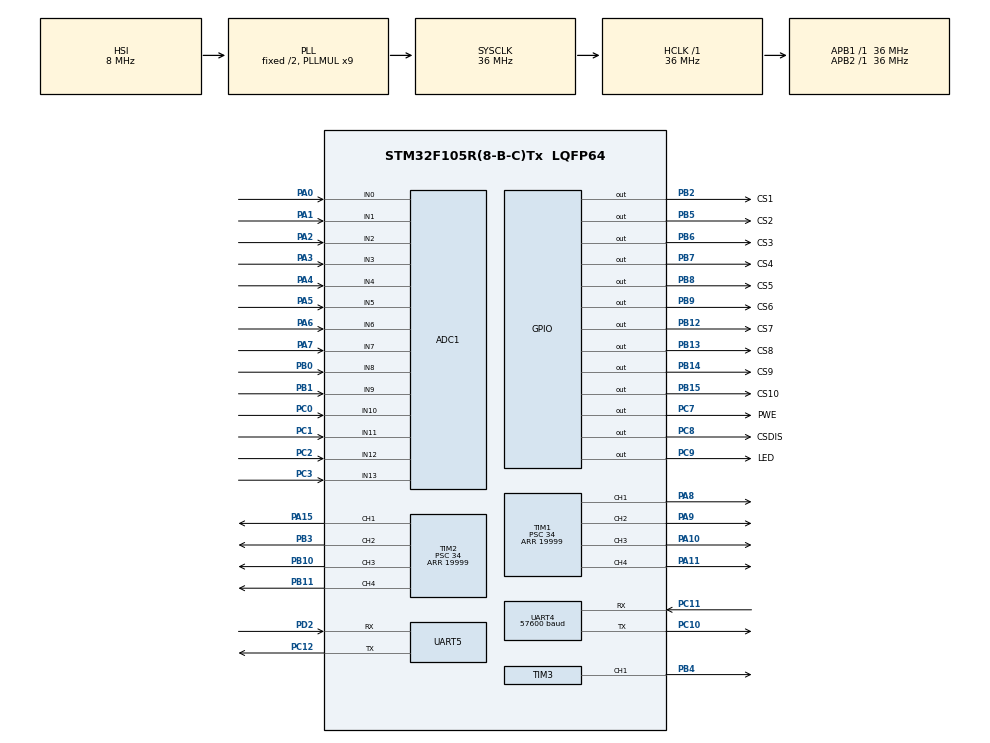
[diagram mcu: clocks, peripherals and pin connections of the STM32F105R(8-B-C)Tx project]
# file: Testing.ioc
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ADC1.Channel-0\#ChannelRegularConversion=ADC_CHANNEL_0
ADC1.Channel-1\#ChannelRegularConversion=ADC_CHANNEL_1
ADC1.Channel-10\#ChannelRegularConversion=ADC_CHANNEL_10
ADC1.Channel-11\#ChannelRegularConversion=ADC_CHANNEL_11
ADC1.Channel-12\#ChannelRegularConversion=ADC_CHANNEL_12
ADC1.Channel-13\#ChannelRegularConversion=ADC_CHANNEL_13
ADC1.Channel-14\#ChannelRegularConversion=ADC_CHANNEL_TEMPSENSOR
ADC1.Channel-2\#ChannelRegularConversion=ADC_CHANNEL_2
ADC1.Channel-3\#ChannelRegularConversion=ADC_CHANNEL_3
ADC1.Channel-4\#ChannelRegularConversion=ADC_CHANNEL_4
ADC1.Channel-5\#ChannelRegularConversion=ADC_CHANNEL_5
ADC1.Channel-6\#ChannelRegularConversion=ADC_CHANNEL_6
ADC1.Channel-7\#ChannelRegularConversion=ADC_CHANNEL_7
ADC1.Channel-8\#ChannelRegularConversion=ADC_CHANNEL_8
ADC1.Channel-9\#ChannelRegularConversion=ADC_CHANNEL_9
ADC1.ContinuousConvMode=ENABLE
ADC1.NbrOfConversion=15
ADC1.NbrOfConversionFlag=1
ADC1.Rank-0\#ChannelRegularConversion=1
ADC1.Rank-1\#ChannelRegularConversion=2
ADC1.Rank-10\#ChannelRegularConversion=11
ADC1.Rank-11\#ChannelRegularConversion=12
ADC1.Rank-12\#ChannelRegularConversion=13
ADC1.Rank-13\#ChannelRegularConversion=14
ADC1.Rank-14\#ChannelRegularConversion=15
ADC1.Rank-2\#ChannelRegularConversion=3
ADC1.Rank-3\#ChannelRegularConversion=4
ADC1.Rank-4\#ChannelRegularConversion=5
ADC1.Rank-5\#ChannelRegularConversion=6
ADC1.Rank-6\#ChannelRegularConversion=7
ADC1.Rank-7\#ChannelRegularConversion=8
ADC1.Rank-8\#ChannelRegularConversion=9
ADC1.Rank-9\#ChannelRegularConversion=10
ADC1.SamplingTime-0\#ChannelRegularConversion=ADC_SAMPLETIME_28CYCLES_5
ADC1.SamplingTime-1\#ChannelRegularConversion=ADC_SAMPLETIME_28CYCLES_5
ADC1.SamplingTime-10\#ChannelRegularConversion=ADC_SAMPLETIME_28CYCLES_5
ADC1.SamplingTime-11\#ChannelRegularConversion=ADC_SAMPLETIME_28CYCLES_5
ADC1.SamplingTime-12\#ChannelRegularConversion=ADC_SAMPLETIME_28CYCLES_5
ADC1.SamplingTime-13\#ChannelRegularConversion=ADC_SAMPLETIME_28CYCLES_5
ADC1.SamplingTime-14\#ChannelRegularConversion=ADC_SAMPLETIME_28CYCLES_5
ADC1.SamplingTime-2\#ChannelRegularConversion=ADC_SAMPLETIME_28CYCLES_5
ADC1.SamplingTime-3\#ChannelRegularConversion=ADC_SAMPLETIME_28CYCLES_5
ADC1.SamplingTime-4\#ChannelRegularConversion=ADC_SAMPLETIME_28CYCLES_5
ADC1.SamplingTime-5\#ChannelRegularConversion=ADC_SAMPLETIME_28CYCLES_5
ADC1.SamplingTime-6\#ChannelRegularConversion=ADC_SAMPLETIME_28CYCLES_5
ADC1.SamplingTime-7\#ChannelRegularConversion=ADC_SAMPLETIME_28CYCLES_5
ADC1.SamplingTime-8\#ChannelRegularConversion=ADC_SAMPLETIME_28CYCLES_5
ADC1.SamplingTime-9\#ChannelRegularConversion=ADC_SAMPLETIME_28CYCLES_5
ADC1.master=1
Dma.ADC1.2.Direction=DMA_PERIPH_TO_MEMORY
Dma.ADC1.2.Instance=DMA1_Channel1
Dma.ADC1.2.MemDataAlignment=DMA_MDATAALIGN_HALFWORD
Dma.ADC1.2.MemInc=DMA_MINC_ENABLE
Dma.ADC1.2.Mode=DMA_CIRCULAR
Dma.ADC1.2.PeriphDataAlignment=DMA_PDATAALIGN_HALFWORD
Dma.ADC1.2.PeriphInc=DMA_PINC_DISABLE
Dma.ADC1.2.Priority=DMA_PRIORITY_LOW
Dma.Request0=UART4_RX
Dma.Request1=UART4_TX
Dma.Request2=ADC1
Dma.UART4_RX.0.Direction=DMA_PERIPH_TO_MEMORY
Dma.UART4_RX.0.Instance=DMA2_Channel3
Dma.UART4_RX.0.MemDataAlignment=DMA_MDATAALIGN_BYTE
Dma.UART4_RX.0.MemInc=DMA_MINC_ENABLE
Dma.UART4_RX.0.Mode=DMA_NORMAL
Dma.UART4_RX.0.PeriphDataAlignment=DMA_PDATAALIGN_BYTE
Dma.UART4_RX.0.PeriphInc=DMA_PINC_DISABLE
Dma.UART4_RX.0.Priority=DMA_PRIORITY_LOW
Dma.UART4_TX.1.Direction=DMA_MEMORY_TO_PERIPH
Dma.UART4_TX.1.Instance=DMA2_Channel5
Dma.UART4_TX.1.MemDataAlignment=DMA_MDATAALIGN_BYTE
Dma.UART4_TX.1.MemInc=DMA_MINC_ENABLE
Dma.UART4_TX.1.Mode=DMA_NORMAL
Dma.UART4_TX.1.PeriphDataAlignment=DMA_PDATAALIGN_BYTE
Dma.UART4_TX.1.PeriphInc=DMA_PINC_DISABLE
Dma.UART4_TX.1.Priority=DMA_PRIORITY_LOW
Mcu.Family=STM32F1
Mcu.Name=STM32F105R(8-B-C)Tx
Mcu.Package=LQFP64
NVIC.DMA1_Channel1_IRQn=true\:0\:0\:false\:false\:true\:false\:true\:true
NVIC.DMA2_Channel3_IRQn=true\:0\:0\:false\:false\:true\:false\:true\:true
NVIC.DMA2_Channel5_IRQn=true\:0\:0\:false\:false\:true\:false\:true\:true
NVIC.PriorityGroup=NVIC_PRIORITYGROUP_4
NVIC.TIM1_BRK_IRQn=true\:0\:0\:false\:false\:true\:true\:true\:true
NVIC.TIM2_IRQn=true\:0\:0\:false\:false\:true\:true\:true\:true
NVIC.UART4_IRQn=true\:0\:0\:false\:false\:true\:true\:true\:true
NVIC.UART5_IRQn=true\:0\:0\:false\:false\:true\:true\:true\:true
PA0-WKUP.Signal=ADCx_IN0
PA1.Signal=ADCx_IN1
PA10.Signal=S_TIM1_CH3
PA11.Signal=S_TIM1_CH4
PA13.Mode=Serial_Wire
PA13.Signal=SYS_JTMS-SWDIO
PA14.Mode=Serial_Wire
PA14.Signal=SYS_JTCK-SWCLK
PA15.Signal=S_TIM2_CH1_ETR
PA2.Signal=ADCx_IN2
PA3.Signal=ADCx_IN3
PA4.Signal=ADCx_IN4
PA5.Signal=ADCx_IN5
PA6.Signal=ADCx_IN6
PA7.Signal=ADCx_IN7
PA8.Signal=S_TIM1_CH1
PA9.Signal=S_TIM1_CH2
PB0.Signal=ADCx_IN8
PB1.Signal=ADCx_IN9
PB10.Signal=S_TIM2_CH3
PB11.Signal=S_TIM2_CH4
PB12.GPIO_Label=CS7
PB12.Signal=GPIO_Output
PB13.GPIO_Label=CS8
PB13.Signal=GPIO_Output
PB14.GPIO_Label=CS9
PB14.Signal=GPIO_Output
PB15.GPIO_Label=CS10
PB15.Signal=GPIO_Output
PB2.GPIO_Label=CS1
PB2.Signal=GPIO_Output
PB3.Signal=S_TIM2_CH2
PB4.Signal=S_TIM3_CH1
PB5.GPIO_Label=CS2
PB5.Signal=GPIO_Output
PB6.GPIO_Label=CS3
PB6.Signal=GPIO_Output
PB7.GPIO_Label=CS4
PB7.Signal=GPIO_Output
PB8.GPIO_Label=CS5
PB8.Signal=GPIO_Output
PB9.GPIO_Label=CS6
PB9.Signal=GPIO_Output
PC0.Signal=ADCx_IN10
PC1.Signal=ADCx_IN11
PC10.Mode=Asynchronous
PC10.Signal=UART4_TX
PC11.Mode=Asynchronous
PC11.Signal=UART4_RX
PC12.Mode=Asynchronous
PC12.Signal=UART5_TX
PC2.Signal=ADCx_IN12
PC3.Signal=ADCx_IN13
PC7.GPIO_Label=PWE
PC7.Signal=GPIO_Output
PC8.GPIO_Label=CSDIS
PC8.Signal=GPIO_Output
PC9.GPIO_Label=LED
PC9.Signal=GPIO_Output
PD2.Mode=Asynchronous
PD2.Signal=UART5_RX
ProjectManager.HeapSize=0x200
ProjectManager.StackSize=0x400
ProjectManager.TargetToolchain=STM32CubeIDE
RCC.ADCPresc=RCC_ADCPCLK2_DIV4
RCC.AHBFreq_Value=36000000
RCC.APB1Freq_Value=36000000
RCC.APB1TimFreq_Value=36000000
RCC.APB2Freq_Value=36000000
RCC.APB2TimFreq_Value=36000000
RCC.HCLKFreq_Value=36000000
RCC.PLLMUL=RCC_PLL_MUL9
RCC.SYSCLKFreq_VALUE=36000000
RCC.SYSCLKSource=RCC_SYSCLKSOURCE_PLLCLK
RCC.USBFreq_Value=24000000
SH.ADCx_IN0.0=ADC1_IN0,IN0
SH.ADCx_IN1.0=ADC1_IN1,IN1
SH.ADCx_IN10.0=ADC1_IN10,IN10
SH.ADCx_IN11.0=ADC1_IN11,IN11
SH.ADCx_IN12.0=ADC1_IN12,IN12
SH.ADCx_IN13.0=ADC1_IN13,IN13
SH.ADCx_IN2.0=ADC1_IN2,IN2
SH.ADCx_IN3.0=ADC1_IN3,IN3
SH.ADCx_IN4.0=ADC1_IN4,IN4
SH.ADCx_IN5.0=ADC1_IN5,IN5
SH.ADCx_IN6.0=ADC1_IN6,IN6
SH.ADCx_IN7.0=ADC1_IN7,IN7
SH.ADCx_IN8.0=ADC1_IN8,IN8
SH.ADCx_IN9.0=ADC1_IN9,IN9
SH.S_TIM1_CH1.0=TIM1_CH1,PWM Generation1 CH1
SH.S_TIM1_CH2.0=TIM1_CH2,PWM Generation2 CH2
SH.S_TIM1_CH3.0=TIM1_CH3,PWM Generation3 CH3
SH.S_TIM1_CH4.0=TIM1_CH4,PWM Generation4 CH4
SH.S_TIM2_CH1_ETR.0=TIM2_CH1,PWM Generation1 CH1
SH.S_TIM2_CH2.0=TIM2_CH2,PWM Generation2 CH2
SH.S_TIM2_CH3.0=TIM2_CH3,PWM Generation3 CH3
SH.S_TIM2_CH4.0=TIM2_CH4,PWM Generation4 CH4
SH.S_TIM3_CH1.0=TIM3_CH1,PWM Generation1 CH1
TIM1.Channel-PWM\ Generation1\ CH1=TIM_CHANNEL_1
TIM1.Channel-PWM\ Generation2\ CH2=TIM_CHANNEL_2
TIM1.Channel-PWM\ Generation3\ CH3=TIM_CHANNEL_3
TIM1.Channel-PWM\ Generation4\ CH4=TIM_CHANNEL_4
TIM1.Period=19999
TIM1.Prescaler=34
TIM1.Pulse-PWM\ Generation1\ CH1=1500
TIM1.Pulse-PWM\ Generation2\ CH2=1500
TIM1.Pulse-PWM\ Generation3\ CH3=1500
TIM1.Pulse-PWM\ Generation4\ CH4=1500
TIM2.Channel-PWM\ Generation1\ CH1=TIM_CHANNEL_1
TIM2.Channel-PWM\ Generation2\ CH2=TIM_CHANNEL_2
TIM2.Channel-PWM\ Generation3\ CH3=TIM_CHANNEL_3
TIM2.Channel-PWM\ Generation4\ CH4=TIM_CHANNEL_4
TIM2.Period=19999
TIM2.Prescaler=34
TIM2.Pulse-PWM\ Generation1\ CH1=1500
TIM2.Pulse-PWM\ Generation2\ CH2=1500
TIM2.Pulse-PWM\ Generation3\ CH3=1500
TIM2.Pulse-PWM\ Generation4\ CH4=1500
TIM3.Channel-PWM\ Generation1\ CH1=TIM_CHANNEL_1
TIM3.Period=19999
TIM3.Prescaler=34
TIM3.Pulse-PWM\ Generation1\ CH1=1500
UART4.BaudRate=57600
UART4.VirtualMode=Asynchronous
UART5.VirtualMode=Asynchronous
VP_ADC1_TempSens_Input.Mode=IN-TempSens
board=custom

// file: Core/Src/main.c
/* USER CODE BEGIN Header */
/**
  ******************************************************************************
  * @file           : main.c
  * @brief          : Main program body
  ******************************************************************************
  * @attention
  *
  * Copyright (c) 2023 STMicroelectronics.
  * All rights reserved.
  *
  * This software is licensed under terms that can be found in the LICENSE file
  * in the root directory of this software component.
  * If no LICENSE file comes with this software, it is provided AS-IS.
  *
  ******************************************************************************
  */
/* USER CODE END Header */
#include "main.h"

/* USER CODE BEGIN Includes */
#include "Thruster.h" //хедр для работы с ВМА
#include "proce_pcb.h"

/* USER CODE END Includes */

/* USER CODE BEGIN PTD */
uint8_t rxFlag;  //флаг о приеме данных
uint16_t data[8] = {0,0,0,0,0,0,0,0}; //ВМА
uint16_t flags;
uint8_t MAX_SIZE = 16;
uint8_t bufferRx[16];
/* USER CODE END PTD */

ADC_HandleTypeDef hadc1;
DMA_HandleTypeDef hdma_adc1;

TIM_HandleTypeDef htim1;
TIM_HandleTypeDef htim2;
TIM_HandleTypeDef htim3;

UART_HandleTypeDef huart4;
UART_HandleTypeDef huart5;
DMA_HandleTypeDef hdma_uart4_rx;
DMA_HandleTypeDef hdma_uart4_tx;

void SystemClock_Config(void);
static void MX_GPIO_Init(void);
static void MX_DMA_Init(void);
static void MX_ADC1_Init(void);
static void MX_TIM1_Init(void);
static void MX_TIM2_Init(void);
static void MX_TIM3_Init(void);
static void MX_UART4_Init(void);
static void MX_UART5_Init(void);

int main(void)
{

  /* MCU Configuration--------------------------------------------------------*/

  /* Reset of all peripherals, Initializes the Flash interface and the Systick. */
  HAL_Init();

  /* Configure the system clock */
  SystemClock_Config();

  /* Initialize all configured peripherals */
  MX_GPIO_Init();
  MX_DMA_Init();
  MX_ADC1_Init();
  MX_TIM1_Init();
  MX_TIM2_Init();
  MX_TIM3_Init();
  MX_UART4_Init();
  MX_UART5_Init();
  /* USER CODE BEGIN 2 */
  HAL_GPIO_TogglePin(LED_GPIO_Port, LED_Pin);
  proce_init();
  /* USER CODE END 2 */

  /* Infinite loop */
  /* USER CODE BEGIN WHILE */

  while (1)
  {

	proce_loop();
//HAL_GPIO_TogglePin(PWE_GPIO_Port, PWE_Pin);
//HAL_GPIO_TogglePin(CS10_GPIO_Port, CS10_Pin);
//HAL_GPIO_TogglePin(CS10_GPIO_Port, CS9_Pin);
//HAL_GPIO_TogglePin(CS10_GPIO_Port, CS8_Pin);
//HAL_GPIO_TogglePin(CS10_GPIO_Port, CS7_Pin);
//HAL_GPIO_TogglePin(CS10_GPIO_Port, CS6_Pin);
//HAL_GPIO_TogglePin(CS10_GPIO_Port, CS5_Pin);
//HAL_GPIO_TogglePin(CS10_GPIO_Port, CS4_Pin);
//HAL_GPIO_TogglePin(CS10_GPIO_Port, CS3_Pin);
//HAL_GPIO_TogglePin(CS10_GPIO_Port, CS2_Pin);
//HAL_GPIO_TogglePin(CS10_GPIO_Port, CS1_Pin);

//HAL_Delay(3000);
//	  if(rxFlag){
//		  rxFlag = 0;
//		//  if(check_crc(bufferRx, MAX_SIZE)){ //если crc совпало
//
//			  data[0] =  (bufferRx[3] << 8) | (bufferRx[2] & 0xff);
//			  data[1] =  (bufferRx[5] << 8) | (bufferRx[4] & 0xff);
//			  data[2] =  (bufferRx[7] << 8) | (bufferRx[6] & 0xff);
//			  data[3] =  (bufferRx[9] << 8) | (bufferRx[8] & 0xff);
//			  data[4] =  (bufferRx[11] << 8) | (bufferRx[10] & 0xff);
//			  data[5] =  (bufferRx[13] << 8) | (bufferRx[12] & 0xff);
//			  data[6] =  (bufferRx[15] << 8) | (bufferRx[14] & 0xff);
//			  data[7] =  (bufferRx[1] << 8) | (bufferRx[0] & 0xff);
//
//			  Thruster_Set_Perc(data); //записываем ширину импульса Ш�?Ма
//			  HAL_GPIO_TogglePin(LED_GPIO_Port, LED_Pin);
//			  HAL_UART_Receive_IT(&huart4, bufferRx, MAX_SIZE);

//			  if(flags & (1 << 7)){  //если 7 бит выствлен
//					HAL_GPIO_WritePin(POWER_ON_GPIO_Port, POWER_ON_Pin, GPIO_PIN_RESET);//выключаем силовое питание
//				}
//		  }
//		  else{
//			  HAL_GPIO_WritePin(LD8_GPIO_Port, LD8_Pin, GPIO_PIN_RESET); //индикация о ошибке приема
//		  }

	  //}

    /* USER CODE END WHILE */

  }
}

void SystemClock_Config(void)
{
  RCC_OscInitTypeDef RCC_OscInitStruct = {0};
  RCC_ClkInitTypeDef RCC_ClkInitStruct = {0};
  RCC_PeriphCLKInitTypeDef PeriphClkInit = {0};

  /** Initializes the RCC Oscillators according to the specified parameters
  * in the RCC_OscInitTypeDef structure.
  */
  RCC_OscInitStruct.OscillatorType = RCC_OSCILLATORTYPE_HSI;
  RCC_OscInitStruct.HSIState = RCC_HSI_ON;
  RCC_OscInitStruct.HSICalibrationValue = RCC_HSICALIBRATION_DEFAULT;
  RCC_OscInitStruct.Prediv1Source = RCC_PREDIV1_SOURCE_HSE;
  RCC_OscInitStruct.PLL.PLLState = RCC_PLL_ON;
  RCC_OscInitStruct.PLL.PLLSource = RCC_PLLSOURCE_HSI_DIV2;
  RCC_OscInitStruct.PLL.PLLMUL = RCC_PLL_MUL9;
  RCC_OscInitStruct.PLL2.PLL2State = RCC_PLL_NONE;
  if (HAL_RCC_OscConfig(&RCC_OscInitStruct) != HAL_OK)
  {
    Error_Handler();
  }

  /** Initializes the CPU, AHB and APB buses clocks
  */
  RCC_ClkInitStruct.ClockType = RCC_CLOCKTYPE_HCLK|RCC_CLOCKTYPE_SYSCLK
                              |RCC_CLOCKTYPE_PCLK1|RCC_CLOCKTYPE_PCLK2;
  RCC_ClkInitStruct.SYSCLKSource = RCC_SYSCLKSOURCE_PLLCLK;
  RCC_ClkInitStruct.AHBCLKDivider = RCC_SYSCLK_DIV1;
  RCC_ClkInitStruct.APB1CLKDivider = RCC_HCLK_DIV1;
  RCC_ClkInitStruct.APB2CLKDivider = RCC_HCLK_DIV1;

  if (HAL_RCC_ClockConfig(&RCC_ClkInitStruct, FLASH_LATENCY_1) != HAL_OK)
  {
    Error_Handler();
  }
  PeriphClkInit.PeriphClockSelection = RCC_PERIPHCLK_ADC;
  PeriphClkInit.AdcClockSelection = RCC_ADCPCLK2_DIV4;
  if (HAL_RCCEx_PeriphCLKConfig(&PeriphClkInit) != HAL_OK)
  {
    Error_Handler();
  }

  /** Configure the Systick interrupt time
  */
  __HAL_RCC_PLLI2S_ENABLE();
}

static void MX_ADC1_Init(void)
{

  ADC_ChannelConfTypeDef sConfig = {0};

  /** Common config
  */
  hadc1.Instance = ADC1;
  hadc1.Init.ScanConvMode = ADC_SCAN_ENABLE;
  hadc1.Init.ContinuousConvMode = ENABLE;
  hadc1.Init.DiscontinuousConvMode = DISABLE;
  hadc1.Init.ExternalTrigConv = ADC_SOFTWARE_START;
  hadc1.Init.DataAlign = ADC_DATAALIGN_RIGHT;
  hadc1.Init.NbrOfConversion = 15;
  if (HAL_ADC_Init(&hadc1) != HAL_OK)
  {
    Error_Handler();
  }

  /** Configure Regular Channel
  */
  sConfig.Channel = ADC_CHANNEL_0;
  sConfig.Rank = ADC_REGULAR_RANK_1;
  sConfig.SamplingTime = ADC_SAMPLETIME_28CYCLES_5;
  if (HAL_ADC_ConfigChannel(&hadc1, &sConfig) != HAL_OK)
  {
    Error_Handler();
  }

  /** Configure Regular Channel
  */
  sConfig.Channel = ADC_CHANNEL_1;
  sConfig.Rank = ADC_REGULAR_RANK_2;
  if (HAL_ADC_ConfigChannel(&hadc1, &sConfig) != HAL_OK)
  {
    Error_Handler();
  }

  /** Configure Regular Channel
  */
  sConfig.Channel = ADC_CHANNEL_2;
  sConfig.Rank = ADC_REGULAR_RANK_3;
  if (HAL_ADC_ConfigChannel(&hadc1, &sConfig) != HAL_OK)
  {
    Error_Handler();
  }

  /** Configure Regular Channel
  */
  sConfig.Channel = ADC_CHANNEL_3;
  sConfig.Rank = ADC_REGULAR_RANK_4;
  if (HAL_ADC_ConfigChannel(&hadc1, &sConfig) != HAL_OK)
  {
    Error_Handler();
  }

  /** Configure Regular Channel
  */
  sConfig.Channel = ADC_CHANNEL_4;
  sConfig.Rank = ADC_REGULAR_RANK_5;
  if (HAL_ADC_ConfigChannel(&hadc1, &sConfig) != HAL_OK)
  {
    Error_Handler();
  }

  /** Configure Regular Channel
  */
  sConfig.Channel = ADC_CHANNEL_5;
  sConfig.Rank = ADC_REGULAR_RANK_6;
  if (HAL_ADC_ConfigChannel(&hadc1, &sConfig) != HAL_OK)
  {
    Error_Handler();
  }

  /** Configure Regular Channel
  */
  sConfig.Channel = ADC_CHANNEL_6;
  sConfig.Rank = ADC_REGULAR_RANK_7;
  if (HAL_ADC_ConfigChannel(&hadc1, &sConfig) != HAL_OK)
  {
    Error_Handler();
  }

  /** Configure Regular Channel
  */
  sConfig.Channel = ADC_CHANNEL_7;
  sConfig.Rank = ADC_REGULAR_RANK_8;
  if (HAL_ADC_ConfigChannel(&hadc1, &sConfig) != HAL_OK)
  {
    Error_Handler();
  }

  /** Configure Regular Channel
  */
  sConfig.Channel = ADC_CHANNEL_8;
  sConfig.Rank = ADC_REGULAR_RANK_9;
  if (HAL_ADC_ConfigChannel(&hadc1, &sConfig) != HAL_OK)
  {
    Error_Handler();
  }

  /** Configure Regular Channel
  */
  sConfig.Channel = ADC_CHANNEL_9;
  sConfig.Rank = ADC_REGULAR_RANK_10;
  if (HAL_ADC_ConfigChannel(&hadc1, &sConfig) != HAL_OK)
  {
    Error_Handler();
  }

  /** Configure Regular Channel
  */
  sConfig.Channel = ADC_CHANNEL_10;
  sConfig.Rank = ADC_REGULAR_RANK_11;
  if (HAL_ADC_ConfigChannel(&hadc1, &sConfig) != HAL_OK)
  {
    Error_Handler();
  }

  /** Configure Regular Channel
  */
  sConfig.Channel = ADC_CHANNEL_11;
  sConfig.Rank = ADC_REGULAR_RANK_12;
  if (HAL_ADC_ConfigChannel(&hadc1, &sConfig) != HAL_OK)
  {
    Error_Handler();
  }

  /** Configure Regular Channel
  */
  sConfig.Channel = ADC_CHANNEL_12;
  sConfig.Rank = ADC_REGULAR_RANK_13;
  if (HAL_ADC_ConfigChannel(&hadc1, &sConfig) != HAL_OK)
  {
    Error_Handler();
  }

  /** Configure Regular Channel
  */
  sConfig.Channel = ADC_CHANNEL_13;
  sConfig.Rank = ADC_REGULAR_RANK_14;
  if (HAL_ADC_ConfigChannel(&hadc1, &sConfig) != HAL_OK)
  {
    Error_Handler();
  }

  /** Configure Regular Channel
  */
  sConfig.Channel = ADC_CHANNEL_TEMPSENSOR;
  sConfig.Rank = ADC_REGULAR_RANK_15;
  if (HAL_ADC_ConfigChannel(&hadc1, &sConfig) != HAL_OK)
  {
    Error_Handler();
  }

}

static void MX_TIM1_Init(void)
{

  TIM_MasterConfigTypeDef sMasterConfig = {0};
  TIM_OC_InitTypeDef sConfigOC = {0};
  TIM_BreakDeadTimeConfigTypeDef sBreakDeadTimeConfig = {0};

  htim1.Instance = TIM1;
  htim1.Init.Prescaler = 34;
  htim1.Init.CounterMode = TIM_COUNTERMODE_UP;
  htim1.Init.Period = 19999;
  htim1.Init.ClockDivision = TIM_CLOCKDIVISION_DIV1;
  htim1.Init.RepetitionCounter = 0;
  htim1.Init.AutoReloadPreload = TIM_AUTORELOAD_PRELOAD_DISABLE;
  if (HAL_TIM_PWM_Init(&htim1) != HAL_OK)
  {
    Error_Handler();
  }
  sMasterConfig.MasterOutputTrigger = TIM_TRGO_RESET;
  sMasterConfig.MasterSlaveMode = TIM_MASTERSLAVEMODE_DISABLE;
  if (HAL_TIMEx_MasterConfigSynchronization(&htim1, &sMasterConfig) != HAL_OK)
  {
    Error_Handler();
  }
  sConfigOC.OCMode = TIM_OCMODE_PWM1;
  sConfigOC.Pulse = 1500;
  sConfigOC.OCPolarity = TIM_OCPOLARITY_HIGH;
  sConfigOC.OCNPolarity = TIM_OCNPOLARITY_HIGH;
  sConfigOC.OCFastMode = TIM_OCFAST_DISABLE;
  sConfigOC.OCIdleState = TIM_OCIDLESTATE_RESET;
  sConfigOC.OCNIdleState = TIM_OCNIDLESTATE_RESET;
  if (HAL_TIM_PWM_ConfigChannel(&htim1, &sConfigOC, TIM_CHANNEL_1) != HAL_OK)
  {
    Error_Handler();
  }
  if (HAL_TIM_PWM_ConfigChannel(&htim1, &sConfigOC, TIM_CHANNEL_2) != HAL_OK)
  {
    Error_Handler();
  }
  if (HAL_TIM_PWM_ConfigChannel(&htim1, &sConfigOC, TIM_CHANNEL_3) != HAL_OK)
  {
    Error_Handler();
  }
  if (HAL_TIM_PWM_ConfigChannel(&htim1, &sConfigOC, TIM_CHANNEL_4) != HAL_OK)
  {
    Error_Handler();
  }
  sBreakDeadTimeConfig.OffStateRunMode = TIM_OSSR_DISABLE;
  sBreakDeadTimeConfig.OffStateIDLEMode = TIM_OSSI_DISABLE;
  sBreakDeadTimeConfig.LockLevel = TIM_LOCKLEVEL_OFF;
  sBreakDeadTimeConfig.DeadTime = 0;
  sBreakDeadTimeConfig.BreakState = TIM_BREAK_DISABLE;
  sBreakDeadTimeConfig.BreakPolarity = TIM_BREAKPOLARITY_HIGH;
  sBreakDeadTimeConfig.AutomaticOutput = TIM_AUTOMATICOUTPUT_DISABLE;
  if (HAL_TIMEx_ConfigBreakDeadTime(&htim1, &sBreakDeadTimeConfig) != HAL_OK)
  {
    Error_Handler();
  }
  HAL_TIM_MspPostInit(&htim1);

}

static void MX_TIM2_Init(void)
{

  TIM_MasterConfigTypeDef sMasterConfig = {0};
  TIM_OC_InitTypeDef sConfigOC = {0};

  htim2.Instance = TIM2;
  htim2.Init.Prescaler = 34;
  htim2.Init.CounterMode = TIM_COUNTERMODE_UP;
  htim2.Init.Period = 19999;
  htim2.Init.ClockDivision = TIM_CLOCKDIVISION_DIV1;
  htim2.Init.AutoReloadPreload = TIM_AUTORELOAD_PRELOAD_DISABLE;
  if (HAL_TIM_PWM_Init(&htim2) != HAL_OK)
  {
    Error_Handler();
  }
  sMasterConfig.MasterOutputTrigger = TIM_TRGO_RESET;
  sMasterConfig.MasterSlaveMode = TIM_MASTERSLAVEMODE_DISABLE;
  if (HAL_TIMEx_MasterConfigSynchronization(&htim2, &sMasterConfig) != HAL_OK)
  {
    Error_Handler();
  }
  sConfigOC.OCMode = TIM_OCMODE_PWM1;
  sConfigOC.Pulse = 1500;
  sConfigOC.OCPolarity = TIM_OCPOLARITY_HIGH;
  sConfigOC.OCFastMode = TIM_OCFAST_DISABLE;
  if (HAL_TIM_PWM_ConfigChannel(&htim2, &sConfigOC, TIM_CHANNEL_1) != HAL_OK)
  {
    Error_Handler();
  }
  if (HAL_TIM_PWM_ConfigChannel(&htim2, &sConfigOC, TIM_CHANNEL_2) != HAL_OK)
  {
    Error_Handler();
  }
  if (HAL_TIM_PWM_ConfigChannel(&htim2, &sConfigOC, TIM_CHANNEL_3) != HAL_OK)
  {
    Error_Handler();
  }
  if (HAL_TIM_PWM_ConfigChannel(&htim2, &sConfigOC, TIM_CHANNEL_4) != HAL_OK)
  {
    Error_Handler();
  }
  HAL_TIM_MspPostInit(&htim2);

}

static void MX_TIM3_Init(void)
{

  TIM_MasterConfigTypeDef sMasterConfig = {0};
  TIM_OC_InitTypeDef sConfigOC = {0};

  htim3.Instance = TIM3;
  htim3.Init.Prescaler = 34;
  htim3.Init.CounterMode = TIM_COUNTERMODE_UP;
  htim3.Init.Period = 19999;
  htim3.Init.ClockDivision = TIM_CLOCKDIVISION_DIV1;
  htim3.Init.AutoReloadPreload = TIM_AUTORELOAD_PRELOAD_DISABLE;
  if (HAL_TIM_PWM_Init(&htim3) != HAL_OK)
  {
    Error_Handler();
  }
  sMasterConfig.MasterOutputTrigger = TIM_TRGO_RESET;
  sMasterConfig.MasterSlaveMode = TIM_MASTERSLAVEMODE_DISABLE;
  if (HAL_TIMEx_MasterConfigSynchronization(&htim3, &sMasterConfig) != HAL_OK)
  {
    Error_Handler();
  }
  sConfigOC.OCMode = TIM_OCMODE_PWM1;
  sConfigOC.Pulse = 1500;
  sConfigOC.OCPolarity = TIM_OCPOLARITY_HIGH;
  sConfigOC.OCFastMode = TIM_OCFAST_DISABLE;
  if (HAL_TIM_PWM_ConfigChannel(&htim3, &sConfigOC, TIM_CHANNEL_1) != HAL_OK)
  {
    Error_Handler();
  }
  HAL_TIM_MspPostInit(&htim3);

}

static void MX_UART4_Init(void)
{

  huart4.Instance = UART4;
  huart4.Init.BaudRate = 57600;
  huart4.Init.WordLength = UART_WORDLENGTH_8B;
  huart4.Init.StopBits = UART_STOPBITS_1;
  huart4.Init.Parity = UART_PARITY_NONE;
  huart4.Init.Mode = UART_MODE_TX_RX;
  huart4.Init.HwFlowCtl = UART_HWCONTROL_NONE;
  huart4.Init.OverSampling = UART_OVERSAMPLING_16;
  if (HAL_UART_Init(&huart4) != HAL_OK)
  {
    Error_Handler();
  }

}

static void MX_UART5_Init(void)
{

  huart5.Instance = UART5;
  huart5.Init.BaudRate = 115200;
  huart5.Init.WordLength = UART_WORDLENGTH_8B;
  huart5.Init.StopBits = UART_STOPBITS_1;
  huart5.Init.Parity = UART_PARITY_NONE;
  huart5.Init.Mode = UART_MODE_TX_RX;
  huart5.Init.HwFlowCtl = UART_HWCONTROL_NONE;
  huart5.Init.OverSampling = UART_OVERSAMPLING_16;
  if (HAL_UART_Init(&huart5) != HAL_OK)
  {
    Error_Handler();
  }

}

static void MX_DMA_Init(void)
{

  /* DMA controller clock enable */
  __HAL_RCC_DMA2_CLK_ENABLE();
  __HAL_RCC_DMA1_CLK_ENABLE();

  /* DMA interrupt init */
  /* DMA1_Channel1_IRQn interrupt configuration */
  HAL_NVIC_SetPriority(DMA1_Channel1_IRQn, 0, 0);
  HAL_NVIC_EnableIRQ(DMA1_Channel1_IRQn);
  /* DMA2_Channel3_IRQn interrupt configuration */
  HAL_NVIC_SetPriority(DMA2_Channel3_IRQn, 0, 0);
  HAL_NVIC_EnableIRQ(DMA2_Channel3_IRQn);
  /* DMA2_Channel5_IRQn interrupt configuration */
  HAL_NVIC_SetPriority(DMA2_Channel5_IRQn, 0, 0);
  HAL_NVIC_EnableIRQ(DMA2_Channel5_IRQn);

}

static void MX_GPIO_Init(void)
{
  GPIO_InitTypeDef GPIO_InitStruct = {0};

  /* GPIO Ports Clock Enable */
  __HAL_RCC_GPIOC_CLK_ENABLE();
  __HAL_RCC_GPIOA_CLK_ENABLE();
  __HAL_RCC_GPIOB_CLK_ENABLE();
  __HAL_RCC_GPIOD_CLK_ENABLE();

  /*Configure GPIO pin Output Level */
  HAL_GPIO_WritePin(GPIOB, CS1_Pin|CS7_Pin|CS8_Pin|CS9_Pin
                          |CS10_Pin|CS2_Pin|CS3_Pin|CS4_Pin
                          |CS5_Pin|CS6_Pin, GPIO_PIN_RESET);

  /*Configure GPIO pin Output Level */
  HAL_GPIO_WritePin(GPIOC, PWE_Pin|CSDIS_Pin|LED_Pin, GPIO_PIN_RESET);

  /*Configure GPIO pins : CS1_Pin CS7_Pin CS8_Pin CS9_Pin
                           CS10_Pin CS2_Pin CS3_Pin CS4_Pin
                           CS5_Pin CS6_Pin */
  GPIO_InitStruct.Pin = CS1_Pin|CS7_Pin|CS8_Pin|CS9_Pin
                          |CS10_Pin|CS2_Pin|CS3_Pin|CS4_Pin
                          |CS5_Pin|CS6_Pin;
  GPIO_InitStruct.Mode = GPIO_MODE_OUTPUT_PP;
  GPIO_InitStruct.Pull = GPIO_NOPULL;
  GPIO_InitStruct.Speed = GPIO_SPEED_FREQ_LOW;
  HAL_GPIO_Init(GPIOB, &GPIO_InitStruct);

  /*Configure GPIO pins : PWE_Pin CSDIS_Pin LED_Pin */
  GPIO_InitStruct.Pin = PWE_Pin|CSDIS_Pin|LED_Pin;
  GPIO_InitStruct.Mode = GPIO_MODE_OUTPUT_PP;
  GPIO_InitStruct.Pull = GPIO_NOPULL;
  GPIO_InitStruct.Speed = GPIO_SPEED_FREQ_LOW;
  HAL_GPIO_Init(GPIOC, &GPIO_InitStruct);

}

/* USER CODE BEGIN 4 */
//void HAL_UART_RxCpltCallback(UART_HandleTypeDef *huart)
//{
//          if(huart == &huart4)
//          {
//                  rxFlag = 1;
//          }
//}
/* USER CODE END 4 */

void Error_Handler(void)
{
  __disable_irq();
  while (1)
  {
  }
}
